# ATmega1281 device description
Architecture: AVR8; Family: megaAVR
Registers are 8-bit, access not given, no defined reset value unless marked. A register's access mark holds for its fields unless they carry their own. Offsets are from the block's base; [hi:lo] are bit positions; {n}, {i} and the like mark numbered series; 'fields as' and 'values as' point back to an identical list.

## TC1 (TC16 module) — Timer/Counter, 16-bit
Instances: TC1 0x00
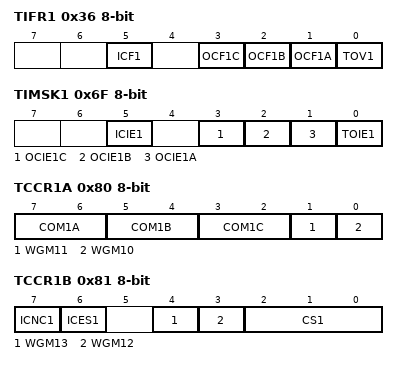
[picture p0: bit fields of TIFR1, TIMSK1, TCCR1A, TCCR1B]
0x36 TIFR1 — Timer/Counter1 Interrupt Flag register
  [5] ICF1 — Input Capture Flag 1
  [3] OCF1C — Output Compare Flag 1C
  [2] OCF1B — Output Compare Flag 1B
  [1] OCF1A — Output Compare Flag 1A
  [0] TOV1 — Timer/Counter1 Overflow Flag
0x6F TIMSK1 — Timer/Counter1 Interrupt Mask Register
  [5] ICIE1 — Timer/Counter1 Input Capture Interrupt Enable
  [3] OCIE1C — Timer/Counter1 Output Compare C Match Interrupt Enable
  [2] OCIE1B — Timer/Counter1 Output Compare B Match Interrupt Enable
  [1] OCIE1A — Timer/Counter1 Output Compare A Match Interrupt Enable
  [0] TOIE1 — Timer/Counter1 Overflow Interrupt Enable
0x80 TCCR1A — Timer/Counter1 Control Register A
  [7:6] COM1A — Compare Output Mode 1A, bits
  [5:4] COM1B — Compare Output Mode 1B, bits
  [3:2] COM1C — Compare Output Mode 1C, bits
  [1] WGM11 — Waveform Generation Mode
  [0] WGM10 — Waveform Generation Mode
0x81 TCCR1B — Timer/Counter1 Control Register B
  [7] ICNC1 — Input Capture 1 Noise Canceler
  [6] ICES1 — Input Capture 1 Edge Select
  [4] WGM13 (bit 2 of the value upward) — Waveform Generation Mode
  [3] WGM12 (bit 2 of the value upward) — Waveform Generation Mode
  [2:0] CS1 — Prescaler source of Timer/Counter 1
    0=No Clock Source (Stopped); 1=Running, No Prescaling; 2=Running, CLK/8; 3=Running, CLK/64; 4=Running, CLK/256; 5=Running, CLK/1024; 6=Running, ExtClk Tx Falling Edge; 7=Running, ExtClk Tx Rising Edge
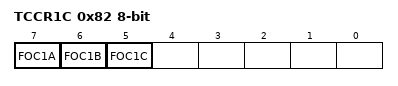
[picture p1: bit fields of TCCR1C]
0x82 TCCR1C — Timer/Counter 1 Control Register C
  [7] FOC1A — Force Output Compare 1A
  [6] FOC1B — Force Output Compare 1B
  [5] FOC1C — Force Output Compare 1C
0x84 TCNT1 16-bit — Timer/Counter1 Bytes
0x86 ICR1 16-bit — Timer/Counter1 Input Capture Register Bytes
0x88 OCR1A 16-bit — Timer/Counter1 Output Compare Register A Bytes
0x8A OCR1B 16-bit — Timer/Counter1 Output Compare Register B Bytes
0x8C OCR1C 16-bit — Timer/Counter1 Output Compare Register C Bytes

## EEPROM
Instances: EEPROM 0x00
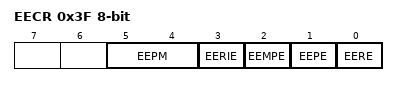
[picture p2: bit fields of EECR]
0x3F EECR — EEPROM Control Register
  [5:4] EEPM — EEPROM Programming Mode Bits
    0=Erase and Write in one operation; 1=Erase Only; 2=Write Only
  [3] EERIE — EEPROM Ready Interrupt Enable
  [2] EEMPE — EEPROM Master Write Enable
  [1] EEPE — EEPROM Write Enable
  [0] EERE — EEPROM Read Enable
0x40 EEDR — EEPROM Data Register
0x41 EEAR 16-bit bits used 11:0 — EEPROM Address Register Low Bytes

## JTAG — JTAG Interface
Instances: JTAG 0x00
0x51 OCDR — On-Chip Debug Related Register in I/O Memory
0x54 MCUSR — MCU Status Register
  [4] JTRF — JTAG Reset Flag
0x55 MCUCR — MCU Control Register
  [7] JTD — JTAG Interface Disable

## EXINT — External Interrupts
Instances: EXINT 0x00
0x3B PCIFR — Pin Change Interrupt Flag Register
  [2:0] PCIF — Pin Change Interrupt Flags
0x3C EIFR — External Interrupt Flag Register
  [7:0] INTF — External Interrupt Flags
0x3D EIMSK — External Interrupt Mask Register
  [7:0] INT — External Interrupt Request 7 Enable
0x68 PCICR — Pin Change Interrupt Control Register
  [2:0] PCIE — Pin Change Interrupt Enables
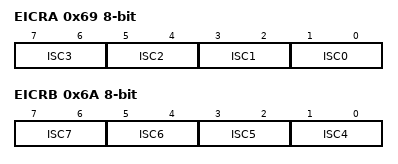
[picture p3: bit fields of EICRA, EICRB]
0x69 EICRA — External Interrupt Control Register A
  [all] fields
    0=Low Level of INTX; 1=Any Logical Change of INTX; 2=Falling Edge of INTX; 3=Rising Edge of INTX
  [2n+1:2n] ISC{n} (n=0..3) — External Interrupt Sense Control Bit
0x6A EICRB — External Interrupt Control Register B
  [all] fields
    values as the fields of EICRA
  [2n-7:2n-8] ISC{n} (n=4..7) — External Interrupt 7-4 Sense Control Bit
0x6B PCMSK0 — Pin Change Mask Register 0
  [7:0] PCINT — Pin Change Enable mask
0x6C PCMSK1 — Pin Change Mask Register 1
  [7:0] PCINT (bit 8 of the value upward) — Pin Change Enable mask
0x6D PCMSK2 — Pin Change Mask Register 2
  [7:0] PCINT (bit 16 of the value upward) — Pin Change Enable mask
